# AE612FA0E5597LS0_CM55_HP_View register map
Vendor: Alif Semiconductor; Series: E6; File version: 1.0
CPU: CM55 r1p0, selectable endian, MPU, FPU, double-precision FPU, DSP, VTOR, 8 interrupt priority bits, 1 SAU regions
Registers are 32-bit, read-write, reset 0x0 unless marked. A register's access mark holds for its fields unless they carry their own. Offsets are from the block's base; [hi:lo] are bit positions; {n}, {i} and the like mark numbered series; 'fields as' and 'values as' point back to an identical list.

## LPI3C
Base 0x43006000
Same registers: I3C 0x49034000
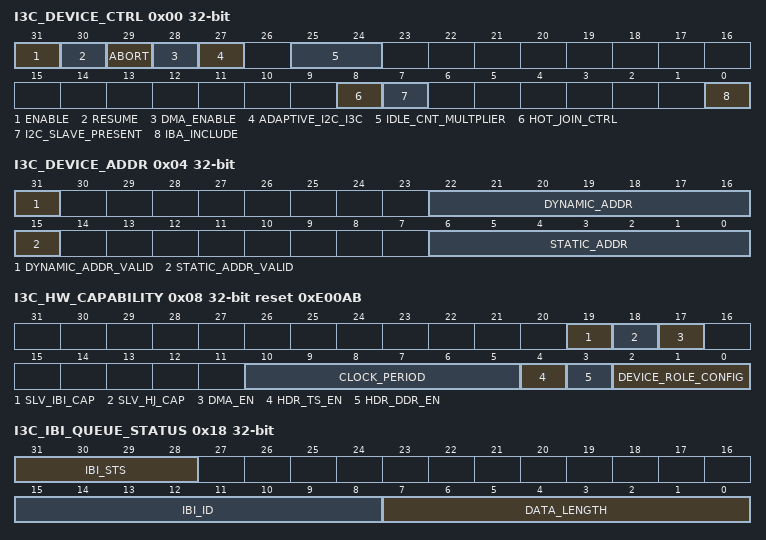
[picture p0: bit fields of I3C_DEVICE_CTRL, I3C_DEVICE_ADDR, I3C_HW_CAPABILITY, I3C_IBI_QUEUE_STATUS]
0x00 I3C_DEVICE_CTRL — Device Control Register
  [31] ENABLE — I3C Controller Enable. This bit controls whether or not I3C is enabled. In master mode of operation, software can disable I3C while it is active. However, the controller may not get disabled immediately and gets disabled after the commands in the command queue (if any) are executed leading to a STOP condition on the bus and the master FSM is in IDLE state (as indicated in I3C_PRESENT_STATE[MASTER_IDLE] bit). In slave mode of operation, software can disable I3C while it is active. However, the disable happens after the ongoing transfer is completed on the I3C bus. Software can read back 0 from this bit once disabling of I3C slave is completed. After POR, the I3C slave controller is enabled by programming this bit to 1. However, the I3C bus interface of the controller responds to transfer on the bus only after it observes 'bus available' condition for I3C_BUS_FREE_AVAIL_TIMING[BUS_AVAILABLE_TIME] x I3C_DEVICE_CTRL[IDLE_CNT_MULTPLIER] counts of PCLK period. Successful completion of enable/disable of the I3C controller depends on the availability of SCL to the controller at the time of performing this operation, and hence may not happen instantly.
    0=Disables the I3C controller; 1=Enables the I3C controller
  [30] RESUME — I3C Controller Resume. This bit is used to resume the controller after it goes to the HALT state. In master mode of operation, the I3C controller goes to the HALT state (as indicated in I3C_PRESENT_STATE[CM_TFR_ST_STS] field) due to any type of error in the transfer. The error type is specified in the response packet available in I3C_RESPONSE_QUEUE_PORT register, as per the value in the ERR_STS field . After the I3C controller goes to the HALT state, the application has to write a 1 to this bit to resume the I3C operation. This bit is auto-cleared once the controller resumes the transfers by initiating the next command. In slave mode of operation, the I3C controller goes to the HALT state due to the following conditions: - Any type of error in the transfer; - I3C_SLV_MAX_LEN[MRL] field updated by the master through SETMRL CCC; After the I3C controller goes to the HALT state, the application has to take necessary action to handle the error condition and then write a 1 to this bit to resume the I3C operation. This bit is auto-cleared once the controller is ready to accept new transfers.
  [29] ABORT — I3C Controller Abort. This bit is used in master mode of operation. This bit allows the I3C controller to relinquish the I3C bus before completing the issued transfer. In response to an ABORT request, the controller issues the STOP condition after the complete data byte is transferred or received. This bit is auto-cleared once the transfer is aborted and the I3C controller issues a 'transfer abort' interrupt (I3C_INTR_STATUS[TRANSFER_ABORT_STS] = 1).
  [28] DMA_ENABLE — DMA Handshake Interface Enable. This bit is used to enable or disable the DMA handshake interface, and is applicable to both master and slave modes of operation.
    0=The DMA handshake control has no significance; 1=Enables the DMA handshake control to interact with external DMA
  [27] ADAPTIVE_I2C_I3C — Adaptive I2C/I3C Mode. This field is used in slave mode of operation. Note: When the I2C mode strap is driven to 0, the slave controller operates in adaptive mode. Setting of this bit is NOT required to put the controller in adaptive mode. It is only used to enable some features of the slave controller to adapt to adaptive I2C/I3C mode of operation. This bit is cleared automatically if the controller determines the mode as I3C. Effect on hot-join: - If this bit is programmed to 1, the controller initiates a hot-join request only after it has switched to I3C mode of operation. - If this bit is programmed to 0, the controller initiates a hot-join without determining the bus mode assuming itself to be on I3C bus. This bit should be set only if the slave application does not know to which bus the device is connected to.
  [25:24] IDLE_CNT_MULTPLIER — Idle Count Multiplier. This bit is used in slave mode of operation. After POR, the slave controller is enabled only after it sees both the SDA and SCL lines IDLE for a specified time. This IDLE time is calculated by multiplying IDLE_CNT_MULTPLIER with the I3C_BUS_FREE_AVAIL_TIMING[BUS_AVAILABLE_TIME] field.
    0=BUS_AVAILABLE_TIME x 1; 1=BUS_AVAILABLE_TIME x 2; 2=BUS_AVAILABLE_TIME x 4; 3=BUS_AVAILABLE_TIME x 8
  [8] HOT_JOIN_CTRL — Hot-Join ACK/NACK Control. This bit is used in master mode of operation. This bit acts as a global control to ACK/NACK the hot-join request from the devices. The I3C master ACK/NACKs the hot-join request from other devices connected on the I3C interface, based on the programming of this bit.
    0=ACK hot-join requests; 1=NACK and send broadcast CCC to disable hot-join
  [7] I2C_SLAVE_PRESENT — I2C Slave Present. This bit is used in master mode of operation. This bit indicates whether any legacy I2C devices are present in the system.
    0=I2C slave not present; 1=I2C slave present
  [0] IBA_INCLUDE — I3C Broadcast Address Include. This bit is used in master mode of operation. This bit is used to include I3C broadcast address (0x7E) for private transfer. Note: If the I3C broadcast address is not included for the private transfers, In-Band Interrupts (IBIs) driven from slaves might not win address arbitration. Hence, the IBIs get delayed.
    0=I3C broadcast address is not included for private transfers; 1=I3C broadcast address is included for private transfers
0x04 I3C_DEVICE_ADDR — Device Address Register
  [31] DYNAMIC_ADDR_VALID — Dynamic Address Valid. This bit is used to control whether the dynamic address set in the DYNAMIC_ADDR field is valid or not. - In I3C main master mode, the user sets this bit to 1 as it self-assigns its dynamic address. - In all other operation modes, the controller sets this bit to 1 when the main master assigns the dynamic address during ENTDAA or SETDASA mechanism. - In I3C slave mode, the controller sets this bit to 1 when the main master assigns the dynamic address during ENTDAA or SETDASA mechanism.
    0=Dynamic address is invalid; 1=Dynamic address is valid
  [22:16] DYNAMIC_ADDR — Device Dynamic Address. This field is used to program the device Dynamic address. The controller uses this address for I3C transfers. In Main Master mode, the application has to program the Dynamic address through the slave interface as it self-assigns its Dynamic address. In all other modes, the Main Master assigns this address during ENTDAA or SETDASA mechanism.
  [15] STATIC_ADDR_VALID — Static Address Valid. In slave mode of operation, this bit reflects the value of static address input port. The input port Static address is expected to be driven to 0x1 only if the device supports I2C or I3C Static address.
    0=Static address is invalid; 1=Static address is valid
  [6:0] STATIC_ADDR — Device Static Address. In Slave mode of operation this field reflects the value of Static address input port. The controller uses this address to respond to SETDASA CCC command to get the Dynamic address if Static address is valid.
0x08 I3C_HW_CAPABILITY ro reset 0xE00AB — Hardware Capability Register
  [19] SLV_IBI_CAP — Specifies slave's capability to initiate in-band interrupt request
    1=Slave IBI request is supported
  [18] SLV_HJ_CAP — Specifies slave's capability to initiate hot-join request
    1=Slave HJ request is supported
  [17] DMA_EN — Specifies whether the controller has DMA handshake interface
    1=DMA handshake interface is supported
  [10:5] CLOCK_PERIOD — Specifies the minimum period of CORE_CLK (ns integers only), that is, the maximum frequency of CORE_CLK that is intended to be fed to I3C.
  [4] HDR_TS_EN — Specifies controller's capability to perform HDR-TS transfers
    0=HDR-TS is not supported
  [3] HDR_DDR_EN — Specifies controller's capability to perform HDR-DDR transfers
    1=HDR-DDR is supported
  [2:0] DEVICE_ROLE_CONFIG — Specifies the configured device role of the I3C controller
    3=Secondary master
0x0C I3C_COMMAND_QUEUE_PORT wo — Command Queue Port Register
  [31:0] COMMAND — 32-bit command
0x10 I3C_RESPONSE_QUEUE_PORT ro — Response Queue Port Register
  [31:0] RESPONSE — 32-bit response
0x14 I3C_RX_DATA_PORT ro — Receive Data Port Register
  [31:0] RX_DATA_PORT — Receive Data Port. The receive data port is mapped to the Rx data buffer. The receive data is always packed in 4-byte aligned data words and stored in the Rx data buffer. If the command length is not aligned to the 4-bytes, then the additional data bytes have to be ignored.
0x14 I3C_TX_DATA_PORT wo (alternate view of I3C_RX_DATA_PORT) — Transmit Data Port Register
  [31:0] TX_DATA_PORT — Transmit Data Port. The transmit data port is mapped to the Tx data buffer. The transmit data should always be packed as 4-byte aligned data words and written to this field. If the command length is not aligned to 4-bytes, then the additional bytes are ignored.
0x18 I3C_IBI_QUEUE_STATUS ro — In-Band Interrupt Queue Status Register
  [31:28] IBI_STS — IBI Received Status. Defines the master response for IBI received. Others: Reserved
    0=Responded with ACK; 1=Responded with NACK
  [15:8] IBI_ID — IBI Identifier. This represents the byte received after START condition: - Device address and R/W bit, in case of SIR or MR IBI; - Hot-Join ID and R/W bit, in case of HJ IBI;
  [7:0] DATA_LENGTH — IBI Data Length. This field represents the length of data received along with the IBI, in bytes.
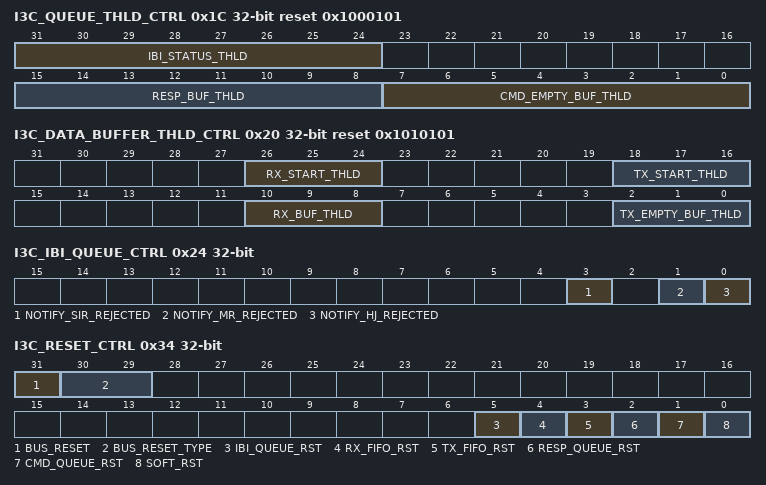
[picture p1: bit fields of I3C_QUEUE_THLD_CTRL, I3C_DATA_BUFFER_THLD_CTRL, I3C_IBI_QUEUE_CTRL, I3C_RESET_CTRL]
0x1C I3C_QUEUE_THLD_CTRL reset 0x1000101 — Queue Threshold Control Register
  [31:24] IBI_STATUS_THLD — In-Band Interrupt Status Threshold Value. Every IBI received by the I3C controller generates an IBI status. This field controls the number of IBI status entries (or greater) in the IBI queue that trigger the I3C_INTR_STATUS[IBI_THLD_STS] interrupt. The valid range is 0 to 15. Software should program only valid values. A value of 0 sets the threshold for 1 entry, and a value of N sets the threshold for N+1 entries.
  [15:8] RESP_BUF_THLD — Response Buffer Threshold Value. Controls the number of entries (or greater) in the response queue that trigger the I3C_INTR_STATUS[RESP_READY_STS] interrupt. The valid range is 0 to 7. Software should program only valid values. A value of 0 sets the threshold for 1 entry, and a value of N sets the threshold for N+1 entries.
  [7:0] CMD_EMPTY_BUF_THLD — Command Buffer Empty Threshold Value. Controls the number of empty locations (or greater) in the command queue that trigger the I3C_INTR_STATUS[CMD_QUEUE_READY_STS] interrupt. The valid range is 0 to 15. Software should program only valid values. A value of 0 sets the threshold to indicate that the queue is completely empty, and a value of N (ranging 1-15) sets the threshold for N entries.
0x20 I3C_DATA_BUFFER_THLD_CTRL reset 0x1010101 — Data Buffer Threshold Control Register
  [26:24] RX_START_THLD — Receive Start Threshold Value. In master mode of operation, when the I3C is set up to initiate a read transfer, it waits until either one of the following conditions is met before it initiates the read transfer on the I3C interface: - Data length (as specified in the command) number of locations are empty in Rx FIFO; - Threshold number of locations (or more) are empty in Rx FIFO; In slave mode of operation, the I3C slave ACKs a write request from a master only if threshold number of empty locations (or more) are available in its receive buffer. The supported values for this field are:
    0=At least 1 empty location; 1=At least 4 empty locations; 2=At least 8 empty locations; 3=At least 16 empty locations; 4=At least 32 empty locations; 5=At least 64 empty locations
  [18:16] TX_START_THLD — Transmit Start Threshold Value. In master mode of operation, when the I3C is set up to initiate a write transfer, it waits until either one of the following conditions is met before it initiates the write transfer on the I3C Interface: - Data length (as specified in the command) number of locations are filled in Tx FIFO; - Threshold number of entries (or more) are available in Tx FIFO; In slave mode of operation, the I3C slave ACKs a read request from a master only if either one of the following conditions is met: - Data length (as specified in the command) number of locations are filled in Tx FIFO; - Threshold number of entries (or more) are available in Tx FIFO; The supported values for this field are:
    0=At least 1 entry; 1=At least 4 entries; 2=At least 8 entries; 3=At least 16 entries; 4=At least 32 entries; 5=At least 64 entries
  [10:8] RX_BUF_THLD — Receive Buffer Threshold Value. This field controls the number of entries (or above) in the Rx FIFO that trigger the I3C_INTR_STATUS[RX_THLD_STS] interrupt. If programmed value is greater than the Rx buffer depth, then the threshold is set to the Rx buffer depth. The supported values for this field are:
    values as TX_START_THLD
  [2:0] TX_EMPTY_BUF_THLD — Transmit Buffer Threshold Value. This field controls the number of empty locations (or above) in the Tx FIFO that trigger the I3C_INTR_STATUS[TX_THLD_STS] interrupt. If programmed value is greater than the Tx buffer depth, then the threshold is set to the Tx buffer depth. The supported values for this field are:
    values as RX_START_THLD
0x24 I3C_IBI_QUEUE_CTRL — IBI Queue Control Register
  [3] NOTIFY_SIR_REJECTED — Notify Rejected Slave Interrupt Request Control. This bit is used to suppress reporting to the application about a Slave Interrupt Request (SIR) being rejected.
    0=Notify SIR rejected disable. Suppress passing the IBI status to the IBI FIFO when a SIR request is NACK-ed and auto-disabled based on the I3C_IBI_SIR_REQ_REJECT register.; 1=Notify SIR rejected enable. Write IBI status to the IBI FIFO when a SIR request is NACK-ed and auto-disabled based on the I3C_IBI_SIR_REQ_REJECT register.
  [1] NOTIFY_MR_REJECTED — Notify Rejected Master Request Control. This bit is used to suppress reporting to the application about a Master Request (MR) being rejected.
    0=Notify MR rejected disable. Suppress passing the IBI status to the IBI FIFO when a MR request is NACK-ed and auto-disabled based on the I3C_IBI_MR_REQ_REJECT register.; 1=Notify MR rejected enable. Write IBI status to the IBI FIFO when a MR request is NACK-ed and auto-disabled based on the I3C_IBI_MR_REQ_REJECT register.
  [0] NOTIFY_HJ_REJECTED — Notify Rejected Hot-Join Control. This bit is used to suppress reporting to the application about a Hot-Join (HJ) request being rejected.
    0=Notify HJ rejected disable. Suppress passing the IBI status to the IBI FIFO when a HJ request is NACK-ed and auto-disabled based on the I3C_DEVICE_CTRL[HOT_JOIN_CTRL] bit.; 1=Notify HJ rejected enable. Write IBI status to the IBI FIFO when a HJ request is NACK-ed and auto-disabled based on the I3C_DEVICE_CTRL[HOT_JOIN_CTRL] bit.
0x2C I3C_IBI_MR_REQ_REJECT — IBI MR Request Rejection Control Register
  [31:0] MR_REQ_REJECT — In-band Master Request Reject. The control bits of this field determine if the I3C controller ACKs an incoming MR or NACKs and disables it. A device-specific policy can be established by appropriately programming this register.
    0=ACK the MR request; 1=NACK and send directed DISEC CCC to disable the interrupting slave
0x30 I3C_IBI_SIR_REQ_REJECT — IBI SIR Request Rejection Control Register
  [31:0] SIR_REQ_REJECT — In-band Slave Interrupt Request Reject. The application of the I3C can decide whether to send an ACK or NACK for a slave interrupt request received from any I3C device. A device-specific response control bit is provided to select the response option. Master ACKs/NACKs the SIR request based on programming of control bit, corresponding to the interrupting device.
    0=ACK the SIR request; 1=NACK and send directed auto-disable CCC
0x34 I3C_RESET_CTRL — Reset Control Register
  [31] BUS_RESET — Bus Reset. This bit is only used in master mode of operation. Write a 1 to this bit to exercise bus reset pattern generation based on the selection in the BUS_RESET_TYPE field. This bit is cleared automatically once the bus reset pattern generation is complete.
  [30:29] BUS_RESET_TYPE — Bus Reset Type. Type of bus reset triggered by BUS_RESET bit. Others: Reserved
    0=HDR exit pattern; 3=SCL timed reset
  [5] IBI_QUEUE_RST — IBI Queue Software Reset. This bit is only used in master mode of operation. Write a 1 to this bit to exercise IBI queue reset. This bit is cleared automatically once the IBI queue reset is complete.
  [4] RX_FIFO_RST — Receive Buffer Software Reset. Write a 1 to this bit to exercise Rx buffer reset. This bit is cleared automatically once the Rx buffer reset is complete.
  [3] TX_FIFO_RST — Transmit Buffer Software Reset. Write a 1 to this bit to exercise Tx buffer reset. This bit is cleared automatically once the Tx buffer reset is complete.
  [2] RESP_QUEUE_RST — Response Queue Software Reset. Write a 1 to this bit to exercise response queue reset. This bit is cleared automatically once the response queue reset is complete.
  [1] CMD_QUEUE_RST — Command Queue Software Reset. Write a 1 to this bit to exercise command queue reset. This bit is cleared automatically once the command queue reset is complete.
  [0] SOFT_RST — Core Software Reset. Write a 1 to this bit to exercise core reset. This resets: - Queues (command, response) and buffers (transmit, receive); - User programmable registers to reflect the reset values; - Pipelining data (if any); - State machines to IDLE state; This bit is cleared automatically once the core reset is complete.
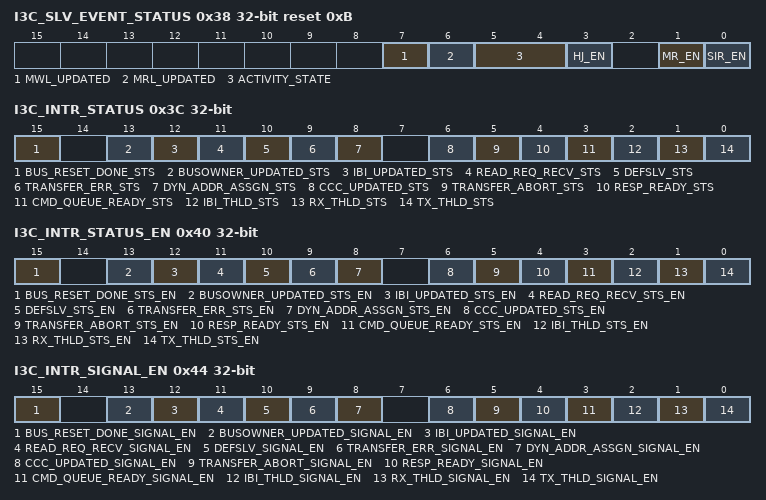
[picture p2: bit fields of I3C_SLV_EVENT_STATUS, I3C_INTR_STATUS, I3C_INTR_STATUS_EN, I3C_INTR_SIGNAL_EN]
0x38 I3C_SLV_EVENT_STATUS reset 0xB — Slave Event Status Register
  [7] MWL_UPDATED write-1-clears — This bit indicates a SETMWL CCC is received by the slave. The updated MWL value can be read from I3C_SLV_MAX_LEN[MWL]. This status can be cleared by writing 0x1 to this bit after reading the updated MWL.
  [6] MRL_UPDATED write-1-clears — This bit indicates a SETMRL CCC is received by the slave. The updated MRL value can be read from I3C_SLV_MAX_LEN[MRL]. This status can be cleared by writing 0x1 to this bit after reading the updated MRL.
  [5:4] ACTIVITY_STATE ro — Activity State Status. This bit reflects the activity state of slave set by the master.
    {v}=ENTAS{v} (v=0..3)
  [3] HJ_EN — Hot-Join Interrupt Enable. This bit reflects whether the HJ request interrupts are allowed on the I3C bus or not. The slave application can choose to disable hot-Join capability of the slave controller (if selected) by setting this bit to 0x0 before enabling the I3C. When done so, the slave does not initiate hot-join and takes part in address assignment without initiating hot-join. If this bit is not set to 0x0 by the slave application, it can be set or cleared by the remote I3C master through ENEC or DISEC CCC. Once disabled, CCC do not have any effect on this bit.
  [1] MR_EN ro — Master Request Enable. In slave mode of operation, this bit reflects whether the controller can initiate the MR request on the I3C bus or not. Usually, this bit is set or cleared by the remote I3C master through ENEC or DISEC CCC.
  [0] SIR_EN ro — Slave Interrupt Request Enable. In slave mode of operation, this bit reflects whether the controller can initiate the SIR request on the I3C bus or not. Usually, this bit is set or cleared by the remote I3C master through ENEC or DISEC CCC.
0x3C I3C_INTR_STATUS — Interrupt Status Register
  [15] BUS_RESET_DONE_STS write-1-clears — Bus Reset Pattern Generation Done Status. This bit is used only in master mode of operation. The interrupt is generated when the SCL Low Timeout Bus Reset Pattern Generation is completed. This bit can be cleared by writing 0x1.
  [13] BUSOWNER_UPDATED_STS write-1-clears — Bus Owner Updated Status. This interrupt is set when the role of the I3C changes from being a master to slave or vice versa. This bit can be cleared by writing 0x1.
  [12] IBI_UPDATED_STS write-1-clears — IBI Updated Status. This bit is used only in slave mode of operation. This bit indicates that the IBI request initiated through SIR request register is addressed and status is updated.
  [11] READ_REQ_RECV_STS write-1-clears — Read Request Received Status. This bit is used only in slave mode of operation. This bit indicates a read request received from the current master when command queue is empty. This bit can be cleared by writing 0x1.
  [10] DEFSLV_STS write-1-clears — Define Slave CCC Received Status. The interrupt is generated if DEFSLV CCC is received. This bit can be cleared by writing 0x1.
  [9] TRANSFER_ERR_STS write-1-clears — Transfer Error Status. The interrupt is generated if any error occurs during transfer. The error type is specified in the response packet associated with the command (in ERR_STS field of the I3C_RESPONSE_QUEUE_PORT register;for details). This bit can be cleared by writing 0x1.
  [8] DYN_ADDR_ASSGN_STS write-1-clears — Dynamic Address Assigned Status. This bit is used only in slave mode of operation. The interrupt is generated if device's dynamic address is assigned through SETDASA or ENTDAA CCC. This bit can be cleared by writing 0x1.
  [6] CCC_UPDATED_STS write-1-clears — CCC Table Updated Status. This bit is used only in slave mode of operation. The interrupt is generated if any of the CCC registers are updated by remote I3C master through CCC commands. This interrupt can be cleared by writing 0x1.
  [5] TRANSFER_ABORT_STS write-1-clears — Transfer Abort Status. This bit is used only in master mode of operation. The interrupt is generated if transfer is aborted. This interrupt can be cleared by writing 0x1.
  [4] RESP_READY_STS ro — Response Queue Ready Status. The interrupt is generated when the number of entries in the RESP queue is greater than or equal to threshold value specified in the I3C_QUEUE_THLD_CTRL[RESP_BUF_THLD] field. This bit is cleared automatically when the number of entries in the RESP queue is less than the specified threshold value.
  [3] CMD_QUEUE_READY_STS ro — Command Queue Ready. The interrupt is generated when the number of empty locations in CMD queue is greater than or equal to threshold value specified in the I3C_QUEUE_THLD_CTRL[CMD_EMPTY_BUF_THLD] field. This bit is cleared automatically when number of empty locations in the CMD queue is less than the specified threshold value.
  [2] IBI_THLD_STS ro — IBI Buffer Threshold Status. This bit is only used in master mode of operation. The interrupt is generated when the number of entries in the IBI buffer is greater than or equal to threshold value specified in the I3C_QUEUE_THLD_CTRL[IBI_STATUS_THLD] field. This bit is cleared automatically when the number of entries in the IBI buffer is less than the specified threshold value.
  [1] RX_THLD_STS ro — Receive Buffer Threshold Status. The interrupt is generated when the number of entries in the Rx buffer is greater than or equal to threshold value specified in the I3C_DATA_BUFFER_THLD_CTRL[RX_BUF_THLD] field. This bit is cleared automatically when the number of entries in the Rx buffer is less than the specified threshold value.
  [0] TX_THLD_STS ro — Transmit Buffer Threshold Status. The interrupt is generated when the number of empty locations in the Tx buffer is greater than or equal to threshold value specified in the I3C_DATA_BUFFER_THLD_CTRL[TX_EMPTY_BUF_THLD] field. This bit is cleared automatically when number of empty locations in the Tx buffer is less than the specified threshold value.
0x40 I3C_INTR_STATUS_EN — Interrupt Status Enable Register
  [15] BUS_RESET_DONE_STS_EN — Bus Reset Pattern Generation Done Status Enable. This bit is used only in master mode of operation.
  [13] BUSOWNER_UPDATED_STS_EN — Bus Owner Updated Status Enable
  [12] IBI_UPDATED_STS_EN — IBI Updated Status Enable. This bit is used in slave mode of operation.
  [11] READ_REQ_RECV_STS_EN — Read Request Received Status Enable. This bit is used in slave mode of operation.
  [10] DEFSLV_STS_EN — Define Slave CCC Received Status Enable
  [9] TRANSFER_ERR_STS_EN — Transfer Error Status Enable
  [8] DYN_ADDR_ASSGN_STS_EN — Dynamic Address Assigned Status Enable. This bit is used in slave mode of operation.
  [6] CCC_UPDATED_STS_EN — CCC Table Updated Status Enable. This bit is used in slave mode of operation.
  [5] TRANSFER_ABORT_STS_EN — Transfer Abort Status Enable. This bit is used only in master mode of operation.
  [4] RESP_READY_STS_EN — Response Queue Ready Status Enable
  [3] CMD_QUEUE_READY_STS_EN — Command Queue Ready Status Enable
  [2] IBI_THLD_STS_EN — IBI Buffer Threshold Status Enable. This bit is used only in master mode of operation.
  [1] RX_THLD_STS_EN — Receive Buffer Threshold Status Enable
  [0] TX_THLD_STS_EN — Transmit Buffer Threshold Status Enable
0x44 I3C_INTR_SIGNAL_EN — Interrupt Signal Enable Register
  [15] BUS_RESET_DONE_SIGNAL_EN — Bus Reset Pattern Generation Done Signal Enable This bit is used only in master mode of operation.
  [13] BUSOWNER_UPDATED_SIGNAL_EN — Bus Owner Updated Signal Enable
  [12] IBI_UPDATED_SIGNAL_EN — IBI Updated Signal Enable. This field is used in slave mode of operation.
  [11] READ_REQ_RECV_SIGNAL_EN — Read Request Received Signal Enable. This field is used in slave mode of operation.
  [10] DEFSLV_SIGNAL_EN — Define Slave CCC Received Signal Enable
  [9] TRANSFER_ERR_SIGNAL_EN — Transfer Error Signal Enable
  [8] DYN_ADDR_ASSGN_SIGNAL_EN — Dynamic Address Assigned Signal Enable. This field is used in slave mode of operation.
  [6] CCC_UPDATED_SIGNAL_EN — CCC Table Updated Signal Enable. This field is used in slave mode of operation.
  [5] TRANSFER_ABORT_SIGNAL_EN — Transfer Abort Signal Enable. This field is used in master mode of operation.
  [4] RESP_READY_SIGNAL_EN — Response Queue Ready Signal Enable
  [3] CMD_QUEUE_READY_SIGNAL_EN — Command Queue Ready Signal Enable
  [2] IBI_THLD_SIGNAL_EN — IBI Buffer Threshold Signal Enable. This field is used in master mode of operation.
  [1] RX_THLD_SIGNAL_EN — Receive Buffer Threshold Signal Enable
  [0] TX_THLD_SIGNAL_EN — Transmit Buffer Threshold Signal Enable
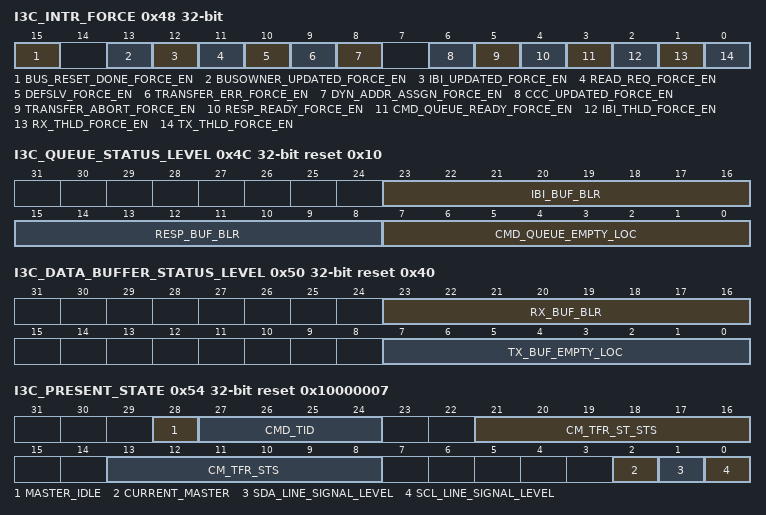
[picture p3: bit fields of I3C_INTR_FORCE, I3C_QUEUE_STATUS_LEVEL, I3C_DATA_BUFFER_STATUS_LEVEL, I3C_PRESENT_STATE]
0x48 I3C_INTR_FORCE — Interrupt Force Enable Register
  [15] BUS_RESET_DONE_FORCE_EN wo — Bus Reset Pattern Generation Done Force Enable. This bit is used only in master mode of operation.
  [13] BUSOWNER_UPDATED_FORCE_EN wo — Bus Owner Updated Force Enable
  [12] IBI_UPDATED_FORCE_EN wo — IBI Updated Force Enable. This bit is used in slave mode of operation.
  [11] READ_REQ_FORCE_EN wo — Read Request Received Force Enable. This bit is used in slave mode of operation.
  [10] DEFSLV_FORCE_EN wo — Define Slave CCC Received Force Enable
  [9] TRANSFER_ERR_FORCE_EN wo — Transfer Error Force Enable
  [8] DYN_ADDR_ASSGN_FORCE_EN wo — Dynamic Address Assigned Force Enable. This bit is used in slave mode of operation.
  [6] CCC_UPDATED_FORCE_EN wo — CCC Table Updated Force Enable. This bit is used in slave mode of operation.
  [5] TRANSFER_ABORT_FORCE_EN wo — Transfer Abort Force Enable. This bit is used in master mode of operation.
  [4] RESP_READY_FORCE_EN wo — Response Queue Ready Force Enable
  [3] CMD_QUEUE_READY_FORCE_EN wo — Command Queue Ready Force Enable
  [2] IBI_THLD_FORCE_EN wo — IBI Buffer Threshold Force Enable. This bit is used in master mode of operation.
  [1] RX_THLD_FORCE_EN wo — Receive Buffer Threshold Force Enable
  [0] TX_THLD_FORCE_EN wo — Transmit Buffer Threshold Force Enable
0x4C I3C_QUEUE_STATUS_LEVEL ro reset 0x10 — Queue Status Level Register
  [23:16] IBI_BUF_BLR — IBI Buffer Level Value. This field contains the number of valid IBI status entries in the IBI buffer. This field is used in master mode of operation.
  [15:8] RESP_BUF_BLR — Response Buffer Level Value. This field contains the number of valid data entries in the response buffer.
  [7:0] CMD_QUEUE_EMPTY_LOC — Command Queue Empty Locations. This field contains the number of empty locations in the command buffer.
0x50 I3C_DATA_BUFFER_STATUS_LEVEL ro reset 0x40 — Data Buffer Status Level Register
  [23:16] RX_BUF_BLR — Receive Buffer Level Value. This field contains the number of valid data entries in the receive buffer.
  [7:0] TX_BUF_EMPTY_LOC — Transmit Buffer Empty Level Value. This field contains the number of empty locations in the transmit buffer.
0x54 I3C_PRESENT_STATE ro reset 0x10000007 — Present State Register
  [28] MASTER_IDLE — Master IDLE. This bit reflects whether the I3C master is in IDLE state or not. This bit is set when all queues (command, response, IBI) and buffers (transmit, receive) are empty and the master FSM is in IDLE state.
    0=I3C master is not in IDLE state; 1=I3C master is in IDLE state
  [27:24] CMD_TID — Command Transaction-ID. This field reflects the Transaction-ID of the currently executing command.
  [21:16] CM_TFR_ST_STS — Current Master Transfer State Status. This field indicates the state of current transfer currently being executed by the I3C. This is valid in master mode only.
    0=IDLE (controller is in IDLE state, waiting for commands from application or slave-initiated IBI); 1=START generation state; 2=RESTART generation state; 3=STOP generation state; 4=START hold generation for the slave-initiated START state; 5=Broadcast write address header (0x7E, W) generation state; 6=Broadcast read address header (0x7E, R) generation state; 7=Dynamic address assignment state; 8=Slave address generation state; 11=CCC byte generation state; 12=HDR command generation state; 13=Write data transfer state; 14=Read data transfer state; 15=IBI (SIR) read data state; 16=IBI auto-disable state; 17=HDR-DDR CRC data generation/receive state; 18=Clock extension state; 19=HALT state (controller is in HALT state, waiting for resume from application through the I3C_DEVICE_CTRL[RESUME] bit)
  [13:8] CM_TFR_STS — Transfer Type Status. This field indicates the type of transfer currently being executed by the I3C. In master mode of operation: 0x0: IDLE (controller is in IDLE state, waiting for commands from application or slave-initiated IBI) 0x1: Broadcast CCC write transfer 0x2: Directed CCC write transfer 0x3: Directed CCC read transfer 0x4: ENTDAA address assignment transfer 0x5: SETDASA address assignment transfer 0x6: Private I3C SDR write transfer 0x7: Private I3C SDR read transfer 0x8: Private I2C SDR write transfer 0x9: Private I2C SDR read transfer 0xC: Private HDR-DDR write transfer 0xD: Private HDR-DDR read transfer 0xE: Servicing IBI transfer 0xF: HALT state (controller is in HALT state, waiting for resume from application through the I3C_DEVICE_CTRL[RESUME] bit) In slave mode of operation: 0x0: IDLE (controller is in IDLE state) 0x1: Hot-join transfer state 0x2: IBI transfer state 0x3: Master write transfer ongoing 0x4: Read data prefetch state 0x5: Master read transfer ongoing 0x6: HALT state (controller is in HALT state, waiting for resume from application through the I3C_DEVICE_CTRL[RESUME] bit)
  [2] CURRENT_MASTER — Current Master. This bit is used to check whether I3C master is current master or not. The current master is the master that owns the SCL line. If this bit is set to 0, I3C master is not current master and requires to request the ownership before initiating any transfer on the line. If this bit is set to 1, I3C master is current master and can initiate transfers on the line.
  [1] SDA_LINE_SIGNAL_LEVEL — SDA Line Signal Level. This bit is used to check the SDA line level to recover from errors and for debugging. It reflects the value of synchronized SDA signal. This is valid in master mode only.
  [0] SCL_LINE_SIGNAL_LEVEL — SCL Line Signal Level. This bit is used to check the SCL line level to recover from errors and for debugging. It reflects the value of synchronized SCL signal. This is valid in master mode only.
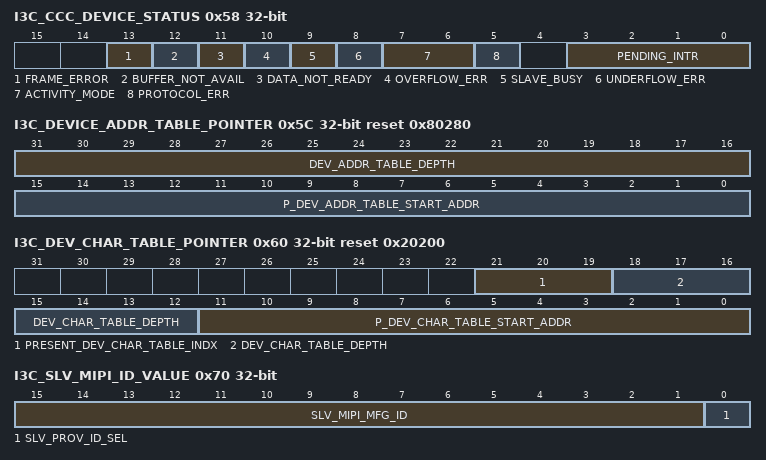
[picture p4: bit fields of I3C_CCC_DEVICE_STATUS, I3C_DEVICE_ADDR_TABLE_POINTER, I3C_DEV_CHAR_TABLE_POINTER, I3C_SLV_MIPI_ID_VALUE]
0x58 I3C_CCC_DEVICE_STATUS ro — Device Operating Status Register
  [13] FRAME_ERROR — Frame Error. This bit is set when private write request from master has frame error in HDR-DDR mode. This is cleared only after master reads the device status through GETSTATUS CCC.
  [12] BUFFER_NOT_AVAIL — Buffer Not Available. This bit is set when private write request from master is NACK-ed because of Rx buffer not having I3C_DATA_BUFFER_THLD_CTRL[RX_BUF_THLD] number of empty locations or response buffer is full. In SDR mode of operation this is cleared when the master issues GETSTATUS CCC or upon space becoming available in the buffer and the successful completion of the next write transfer. In HDR mode of operation it is cleared only when the master issues GETSTATUS CCC.
  [11] DATA_NOT_READY — Data Not Ready. This bit is set when private read request from master is NACK-ed because of any of the following conditions: - Command FIFO empty; - Tx FIFO threshold is not met; - Response FIFO full;
  [10] OVERFLOW_ERR — Overflow Error. Overflow error condition detected during master write transfer. This is cleared only after master reads the device status through GETSTATUS CCC.
  [9] SLAVE_BUSY — Slave Busy. This bit is set if any change is made by the current master in to MRL register or occurance of any error. It is cleared after slave application resumes the slave operation by writing 1 to the I3C_DEVICE_CTRL[RESUME] bit.
  [8] UNDERFLOW_ERR — Underflow Error. This bit is set if I3C slave terminates a read transfer because of unavailability of data in the transmit buffer. This is cleared only after master reads the device status through GETSTATUS CCC.
  [7:6] ACTIVITY_MODE — Activity Mode. This field reflects the input port signal ACT_MODE.
  [5] PROTOCOL_ERR — Protocol Error. This bit is set when the slave controller encounters a parity/CRC error during write data transfer.
  [3:0] PENDING_INTR — Pending Interrupt. This field reflects the value driven on PENDING_INT input port.
0x5C I3C_DEVICE_ADDR_TABLE_POINTER ro reset 0x80280 — Pointer for Device Address Table Registers
  [31:16] DEV_ADDR_TABLE_DEPTH — Depth of Device Address Table
  [15:0] P_DEV_ADDR_TABLE_START_ADDR — Start Address of Device Address Table
0x60 I3C_DEV_CHAR_TABLE_POINTER reset 0x20200 — Pointer for Device Characteristics Table Register
  [21:19] PRESENT_DEV_CHAR_TABLE_INDX — Current Index of Device Characteristics Table. This field returns the current location of the Device Characteristics Table (DCT) index. Initially, this index points to 0. Once the complete characteristics information of a slave device is written into DCT during ENTDAA, this index increments by 1. The first winning device information is stored into DCT index 0, the second winning device information into DCT index 1, and so on. If required, this index is used to override the location, where the characteristic information of the slave devices on the I3C bus is written during ENTDAA. Hence, this bit is useful only if the device is current master. During DEFSLV CCC, the index always starts from 0. In non-current master, this bit is always read-only.
  [18:12] DEV_CHAR_TABLE_DEPTH ro — Depth of Device Characteristics Table
  [11:0] P_DEV_CHAR_TABLE_START_ADDR ro — Start Address of Device Characteristics Table
0x6C I3C_VENDOR_SPECIFIC_REG_POINTER ro reset 0xB0 — Pointer for Vendor Specific Registers
  [15:0] P_VENDOR_REG_START_ADDR — Start Address of Vendor Specific Registers
0x70 I3C_SLV_MIPI_ID_VALUE — Manufacturer ID Register
  [15:1] SLV_MIPI_MFG_ID — Specifies the MIPI Manufacturer ID of the I3C device, PID[47-33]
  [0] SLV_PROV_ID_SEL — Specifies the Provisional ID type of the I3C device, PID[32]
    0=Vendor-fixed value; 1=Random value
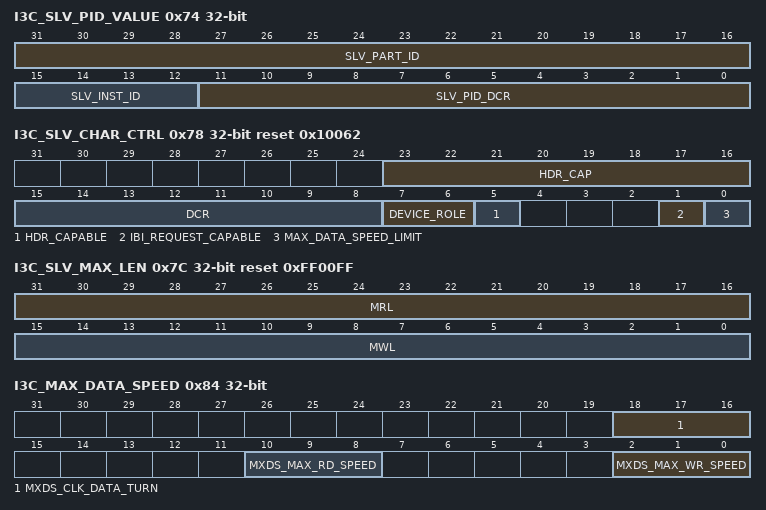
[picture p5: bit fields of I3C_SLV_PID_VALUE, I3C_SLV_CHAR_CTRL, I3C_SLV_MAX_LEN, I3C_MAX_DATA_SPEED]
0x74 I3C_SLV_PID_VALUE — Provisional ID Register
  [31:16] SLV_PART_ID — Specifies the Part ID of the I3C device, PID[31-16]
  [15:12] SLV_INST_ID — Specifies the Instance ID of the I3C device, PID[15-12]
  [11:0] SLV_PID_DCR — Specifies the additional 12-bit ID of the I3C device, PID[11-0]
0x78 I3C_SLV_CHAR_CTRL reset 0x10062 — I3C Slave Characteristic Register
  [23:16] HDR_CAP ro — I3C Device HDR Capability Field Value.
    1=HDR Mode 0 (HDR-DDR)
  [15:8] DCR — I3C Device Characteristic Value.
  [7:6] DEVICE_ROLE — Device Role Field in Bus Characteristic Register, BCR[7:6]. This field is set to 0x1 by default, because the I3C is configured to a 'secondary master' device role. The application is not expected to change the role once configured. But if the application chooses to operate the secondary master configuration as slave-only through programming, then the device role can be overwritten as a slave (BCR[7:6] = 0x0). This field is reset to its default value upon HW/SW reset. Software must program the values again after issuing reset.
  [5] HDR_CAPABLE — HDR Capable Field in Bus Characteristic Register, BCR[5]. This field is set to 0x1 by default, because the I3C is configured to support HDR mode. Note that programming this bit to 0x0 does not disable the HDR feature itself. This bit can be modified by the application if it does not want to advertize slave's HDR capability to master. This field is reset to its default value upon HW/SW reset. Software must program the values again after issuing reset.
  [1] IBI_REQUEST_CAPABLE ro — IBI Request Capable Field in Bus Characteristic Register, BCR[1].
    1=Slave IBI is supported
  [0] MAX_DATA_SPEED_LIMIT — Max Data Speed Limitation Field in Bus Characteristic Register, BCR[0]. Specifies whether or not I3C has maximum data speed limitation. If this bit is set to 0, controller NACK-ed the GETMXDS CCC sent by the master. If this bit is set to 1, controller returns the data in I3C_MAX_DATA_SPEED and I3C_MAX_READ_TURNAROUND registers in response to the GETMXDS CCC sent by the master. This field is reset to its default value upon HW/SW reset. Software must program the values again after issuing reset.
0x7C I3C_SLV_MAX_LEN ro reset 0xFF00FF — I3C Max Write/Read Length Register
  [31:16] MRL — I3C Device Max Read Length
  [15:0] MWL — I3C Device Max Write Length
0x80 I3C_MAX_READ_TURNAROUND ro — MXDS Maximum Read Turnaround Time Register
  [23:0] MXDS_MAX_RD_TURN — Specifies the maximum read turnaround time (in us) of I3C slave. A value of 0 indicates that I3C slave supports GETMXDS Format 1 (two data bytes).
0x84 I3C_MAX_DATA_SPEED — MXDS Maximum Data Speed Register
  [18:16] MXDS_CLK_DATA_TURN — Specifies the clock to data turnaround time of I3C slave device.
    {v}={v+8} ns (v=0..4)
  [10:8] MXDS_MAX_RD_SPEED — Specifies the Maximum Sustained Data Rate for non-CCC messages sent by I3C slave device to master device.
    0=12.5 MHz; 1=8 MHZ; 2=6 MHz; 3=4 MHz; 4=2 MHz
  [2:0] MXDS_MAX_WR_SPEED — Specifies the Maximum Sustained Data Rate for non-CCC messages sent by master device to I3C slave device.
    0=12.5 MHz; 1=8 MHZ; 2=6 MHz; 3=4 MHz; 4=2 MHz
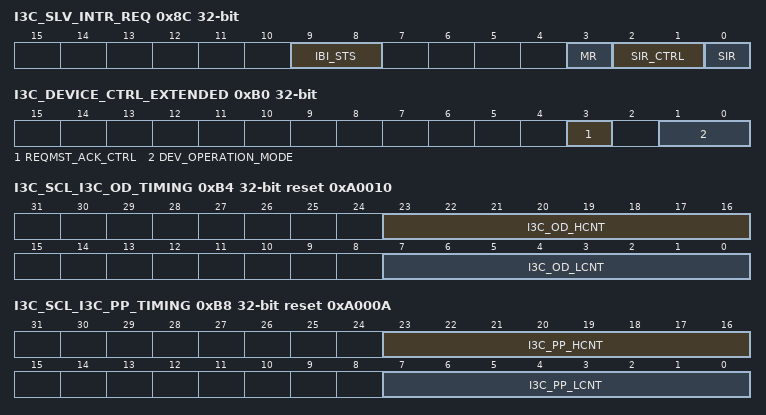
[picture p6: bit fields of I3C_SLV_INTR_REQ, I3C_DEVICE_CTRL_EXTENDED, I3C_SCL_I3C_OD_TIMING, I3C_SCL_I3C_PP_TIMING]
0x8C I3C_SLV_INTR_REQ — Slave Interrupt Request Register
  [9:8] IBI_STS ro — IBI Completion Status. This field is common for SIR and MR. The controller does not attempt to issue the IBI and generates the IBI completion status as 0x3 if one of the following condition is true: - Master has not assigned the dynamic address; - Master has cleared the assigned dynamic address (through RSTDAA CCC); - Master has disabled the IBI event (through DISEC CCC); - The controller has switched the role to master;
    1=IBI accepted by the master (ACK response received); 3=IBI not attempted
  [3] MR — Master Request. When set, the controller attempts to issue the MR on the I3C bus. Once issued and when the current master accepts (ACK) or if the controller is unable to issue the MR, then the controller clears this bit automatically and updates the IBI_STS field. If NACK response is received for the MR, then the controller re-attempts the MR upon detecting the next START condition from the master or after the 'bus available' time. Once set, the application cannot clear this bit.
  [2:1] SIR_CTRL — Slave Interrupt Request Control.
    0=Send the assigned dynamic address
  [0] SIR — Slave Interrupt Request. When set, the controller attempts to issue the SIR on the I3C bus. Once issued and when the current master accepts (ACK) or if the controller is unable to issue the SIR, then the controller clears this bit automatically and updates the IBI_STS field. If NACK response is received for the SIR, then the controller re-attempts the SIR upon detecting the next START condition from the master or after the 'bus available' time. Once set, the application cannot clear this bit.
0xB0 I3C_DEVICE_CTRL_EXTENDED — Device Control Extended Register
  [3] REQMST_ACK_CTRL — In slave mode of operation, this bit serves as a control to ACK / NACK GETACCMST CCC from current master.
    0=ACK GETACCMST CCC; 1=NACK GETACCMST CCC
  [1:0] DEV_OPERATION_MODE — This field is used to select the device operation mode before the I3C is enabled. This field is written only when the I3C is disabled. This field is automatically updated by the I3C once the role change happens in secondary master mode.
    0=Master; 1=Slave
0xB4 I3C_SCL_I3C_OD_TIMING reset 0xA0010 — SCL I3C Open Drain Timing Register
  [23:16] I3C_OD_HCNT — I3C Open-Drain High Count. SCL open-drain high count timing for I3C transfers.
  [7:0] I3C_OD_LCNT — I3C Open-Drain Low Count. SCL open-drain low count timing for I3C transfers.
0xB8 I3C_SCL_I3C_PP_TIMING reset 0xA000A — SCL I3C Push Pull Timing Register
  [23:16] I3C_PP_HCNT — I3C Push-Pull High Count. SCL push-pull high count timing for I3C transfers.
  [7:0] I3C_PP_LCNT — I3C Push-Pull Low Count. SCL push-pull low count timing for I3C transfers.
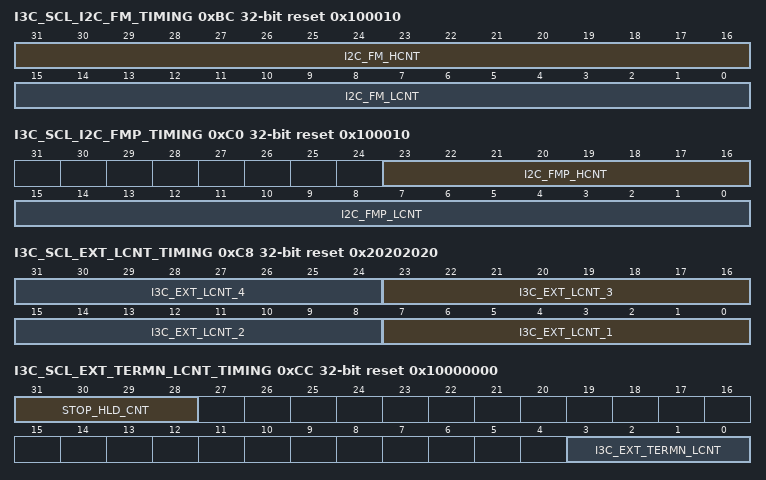
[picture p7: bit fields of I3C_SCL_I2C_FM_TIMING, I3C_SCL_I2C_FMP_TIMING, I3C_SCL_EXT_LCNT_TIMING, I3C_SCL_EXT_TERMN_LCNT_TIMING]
0xBC I3C_SCL_I2C_FM_TIMING reset 0x100010 — SCL I2C Fast Mode Timing Register
  [31:16] I2C_FM_HCNT — I2C Fast Mode High Count. The SCL open-drain high count timing for I2C FM transfers.
  [15:0] I2C_FM_LCNT — I2C Fast Mode Low Count. The SCL open-drain low count timing for I2C FM transfers.
0xC0 I3C_SCL_I2C_FMP_TIMING reset 0x100010 — SCL I2C Fast Mode Plus Timing Register
  [23:16] I2C_FMP_HCNT — I2C Fast Mode Plus High Count. The SCL open-drain high count timing for I2C FM+ transfers.
  [15:0] I2C_FMP_LCNT — I2C Fast Mode Plus Low Count. The SCL open-drain low count timing for I2C FM+ transfers.
0xC8 I3C_SCL_EXT_LCNT_TIMING reset 0x20202020 — SCL Extended Low Count Timing Register
  [8n-1:8n-8] I3C_EXT_LCNT_{n} (n=1..4) — I3C Extended Low Count Register {n}. SDR{n} uses this field for data transfer.
0xCC I3C_SCL_EXT_TERMN_LCNT_TIMING reset 0x10000000 — SCL Termination Bit Low Count Timing Register
  [31:28] STOP_HLD_CNT — Stop Hold Count. Stop hold count in terms of CORE_CLKs which is used for 'stop hold' generation in master mode.
  [3:0] I3C_EXT_TERMN_LCNT — I3C Extended Read Termination Bit Low Count. Effective termination bit low period is derived based on the SDR speed. SDR0 speed: I3C_PP_LCNT + I3C_EXT_TERMN_LCNT SDR1 speed: I3C_EXT_LCNT_1 + I3C_EXT_TERMN_LCNT SDR2 speed: I3C_EXT_LCNT_2 + I3C_EXT_TERMN_LCNT SDR3 speed: I3C_EXT_LCNT_3 + I3C_EXT_TERMN_LCNT SDR4 speed: I3C_EXT_LCNT_4 + I3C_EXT_TERMN_LCNT
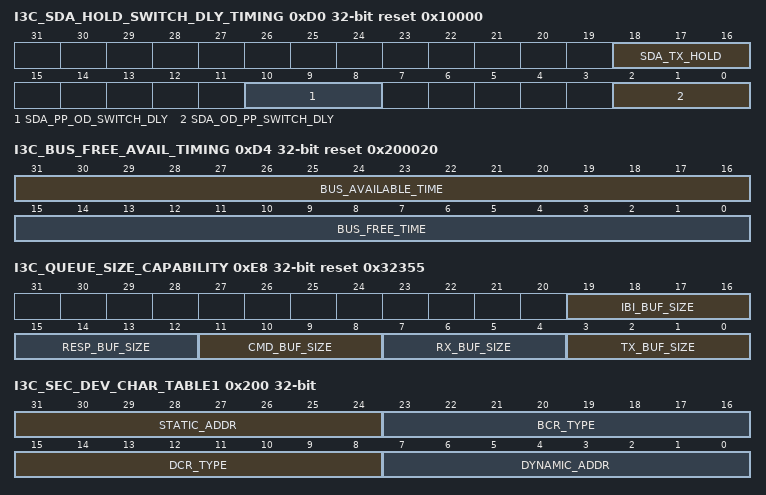
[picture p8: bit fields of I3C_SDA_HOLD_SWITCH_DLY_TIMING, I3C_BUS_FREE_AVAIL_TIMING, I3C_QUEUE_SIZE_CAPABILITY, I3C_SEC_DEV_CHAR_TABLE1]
0xD0 I3C_SDA_HOLD_SWITCH_DLY_TIMING reset 0x10000 — SDA Hold and Mode Switch Delay Timing Register
  [18:16] SDA_TX_HOLD — This field controls the hold time (in term of the CORE_CLK periods) of the transmit data (SDA) with respect to the SCL edge in the FM, FM+, SDR and DDR speed modes. The valid values are from 0x1 to 0x7. Others are reserved.
  [10:8] SDA_PP_OD_SWITCH_DLY — This field is used to delay the sda_out with respect to sda_oe (in terms of CORE_CLK period) while switching the transfer from PP1 (Push-Pull Mode SDA = 1) to OD1 (Open-Drain SDA = 1). The valid value can range from 0 to 4. Others are reserved.
  [2:0] SDA_OD_PP_SWITCH_DLY — This field is used to delay the sda_oe with respect to sda_out (in terms of CORE_CLK period) while switching the transfer from OD1 (Open-Drain Mode SDA = 1) to PP1 (Push-Pull Mode SDA = 1). The valid value can range from 0 to 4. Others are reserved.
0xD4 I3C_BUS_FREE_AVAIL_TIMING reset 0x200020 — Bus Free Timing Register
  [31:16] BUS_AVAILABLE_TIME — Bus Available Count Value. This field is used only in slave mode of operation. This field is used by the slave / non-current master to initiate an IBI after STOP condition.
  [15:0] BUS_FREE_TIME — Bus Free Count Value. This field is used only in master mode of operation. In pure bus system, this field represents tCAS parameter. In mixed bus system, this field is expected to be programmed to tLOW of I2C timing.
0xD8 I3C_BUS_IDLE_TIMING reset 0x20 — Bus Idle Timing Register
  [19:0] BUS_IDLE_TIME — Bus Idle Count Value. This field is used by the controller in slave or non-current master mode to initiate a hot-join request if the dynamic address is not valid.
0xDC I3C_SCL_LOW_MST_EXT_TIMEOUT reset 0x3567E0 — SCL Low Master Extended Timeout Register
  [25:0] SCL_LOW_MST_TIMEOUT_COUNT — This count defines the number of CORE_CLK periods to count for generation of the SCL low bus reset pattern.
0xE0 I3C_VER_ID ro reset 0x3130312A — Version ID Register
  [31:0] I3C_VER_ID — Current release number. An application reading this register along with the I3C_VER_TYPE register gathers details of the current release.
0xE4 I3C_VER_TYPE ro reset 0x6C633030 — Version Type Register
  [31:0] I3C_VER_TYPE — Current release type. An application reading this register along with the I3C_VER_ID register gathers details of the current release.
0xE8 I3C_QUEUE_SIZE_CAPABILITY ro reset 0x32355
  [19:16] IBI_BUF_SIZE — IBI Queue Size
    3=16 DWORDS
  [15:12] RESP_BUF_SIZE — Response Queue Size
    2=8 DWORDS
  [11:8] CMD_BUF_SIZE — Command Queue Size
    3=16 DWORDS
  [7:4] RX_BUF_SIZE — Receive Data Buffer Size
    5=64 DWORDS
  [3:0] TX_BUF_SIZE — Transmit Data Buffer Size
    5=64 DWORDS
0x200 I3C_DEV_CHAR_TABLE1_LOC1 ro — Device Characteristic Table Location 1 Register
  [31:0] MSB_PROVISIONAL_ID — The MSB 32-bit value of Provisional-ID
0x200 I3C_SEC_DEV_CHAR_TABLE1 ro (alternate view of I3C_DEV_CHAR_TABLE1_LOC1) — Secondary Master Device Characteristic Table Location Register
  [31:24] STATIC_ADDR — The Static Address of Device
  [23:16] BCR_TYPE — The BCR Type of Device
  [15:8] DCR_TYPE — The DCR Type of Device
  [7:0] DYNAMIC_ADDR — The Dynamic Address of Device
0x204 I3C_DEV_CHAR_TABLE1_LOC2 ro — Device Characteristic Table Location 2 Register
  [15:0] LSB_PROVISIONAL_ID — The LSB 16-bit value of Provisional-ID
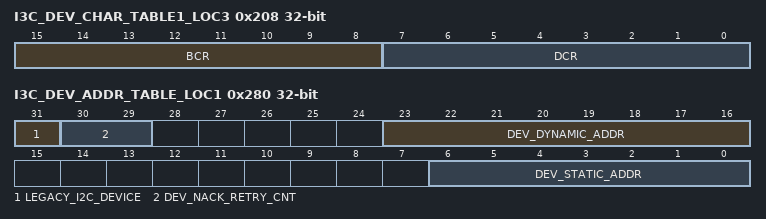
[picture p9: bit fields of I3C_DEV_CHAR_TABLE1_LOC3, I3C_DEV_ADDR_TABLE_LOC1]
0x208 I3C_DEV_CHAR_TABLE1_LOC3 ro — Device Characteristic Table Location 3 Register
  [15:8] BCR — Bus Characteristic Value
  [7:0] DCR — Device Characteristic Value
0x20C I3C_DEV_CHAR_TABLE1_LOC4 ro — Device Characteristic Table Location 4 Register
  [7:0] DEV_DYNAMIC_ADDR — Device Dynamic Address assigned.
0x280 I3C_DEV_ADDR_TABLE_LOC1 — Device Address Table Location 1 Register
  [31] LEGACY_I2C_DEVICE — Legacy I2C Device or Not. This bit should be set to 1 if the device is a legacy I2C device.
  [30:29] DEV_NACK_RETRY_CNT — Device NACK Retry Count. This field is used to set Device NACK Retry Count for the particular device. If the device NACKs for the device address, the I3C automatically retries the same device until this count expires. If the slave does not ACK for the mentioned number of retries, then I3C generates an error response and moves to the HALT state. This feature is used for Retry Model for the following features in the I3C specification: - Retry Model for Direct GET CCC Commands. - The incoming SIR-IBI matches with the slave address initiated by the master.
  [23:16] DEV_DYNAMIC_ADDR — Device Dynamic Address with Parity. This field consists of dynamic address and parity bit. The LSB bits [22:16] should consist of 7-bit dynamic address field indicating the address to be assigned for the winning I3C device when using the ENTDAA command. The MSB bit [23] is the odd parity of the 7-bit dynamic address used for the ENTDAA address assignment (~XOR(DEV_DYNAMIC_ADDR[22:16]).
  [6:0] DEV_STATIC_ADDR — Device Static Address
